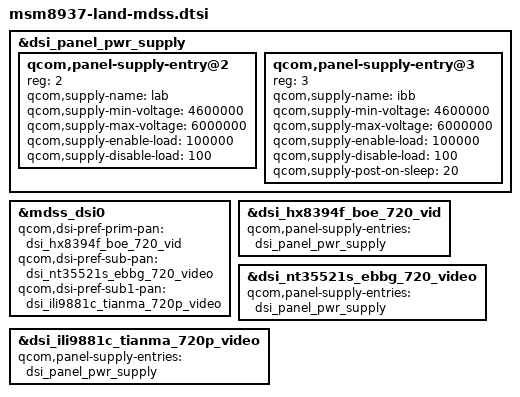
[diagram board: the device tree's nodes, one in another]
#include "dsi-panel-hx8394f-boe-720p-video.dtsi"
#include "dsi-panel-nt35521s-ebbg-720p-video.dtsi"
#include "dsi-panel-ili9881c-tianma-720p-video.dtsi"

&dsi_panel_pwr_supply {
	qcom,panel-supply-entry@2 {
		reg = <2>;
		qcom,supply-name = "lab";
		qcom,supply-min-voltage = <4600000>;
		qcom,supply-max-voltage = <6000000>;
		qcom,supply-enable-load = <100000>;
		qcom,supply-disable-load = <100>;
	};

	qcom,panel-supply-entry@3 {
		reg = <3>;
		qcom,supply-name = "ibb";
		qcom,supply-min-voltage = <4600000>;
		qcom,supply-max-voltage = <6000000>;
		qcom,supply-enable-load = <100000>;
		qcom,supply-disable-load = <100>;
		qcom,supply-post-on-sleep = <20>;
	};
};


&mdss_dsi0 {
	qcom,dsi-pref-prim-pan = <&dsi_hx8394f_boe_720_vid>;
	qcom,dsi-pref-sub-pan = <&dsi_nt35521s_ebbg_720_video>;
	qcom,dsi-pref-sub1-pan = <&dsi_ili9881c_tianma_720p_video>;
};

&dsi_hx8394f_boe_720_vid {
	qcom,panel-supply-entries = <&dsi_panel_pwr_supply>;
};

&dsi_nt35521s_ebbg_720_video {
	qcom,panel-supply-entries = <&dsi_panel_pwr_supply>;
};

&dsi_ili9881c_tianma_720p_video {
	qcom,panel-supply-entries = <&dsi_panel_pwr_supply>;
};

